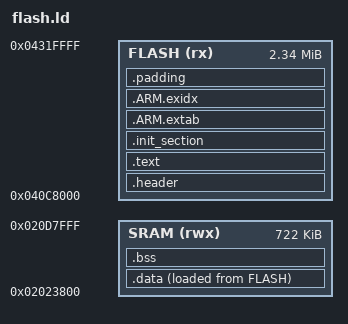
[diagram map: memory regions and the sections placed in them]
/****************************************************************************
 *
 * Copyright 2017 Samsung Electronics All Rights Reserved.
 *
 * Licensed under the Apache License, Version 2.0 (the "License");
 * you may not use this file except in compliance with the License.
 * You may obtain a copy of the License at
 *
 * http://www.apache.org/licenses/LICENSE-2.0
 *
 * Unless required by applicable law or agreed to in writing,
 * software distributed under the License is distributed on an
 * "AS IS" BASIS, WITHOUT WARRANTIES OR CONDITIONS OF ANY KIND,
 * either express or implied. See the License for the specific
 * language governing permissions and limitations under the License.
 *
 ****************************************************************************/
/****************************************************************************
 * configs/sidk_s5jt200/scripts/ld_s5jt200_flash.script
 *
 *   Copyright (C) 2011-2013 Gregory Nutt. All rights reserved.
 *   Author: Gregory Nutt <gnutt@nuttx.org>
 *           Laurent Latil <laurent@latil.nom.fr>
 *
 * Redistribution and use in source and binary forms, with or without
 * modification, are permitted provided that the following conditions
 * are met:
 *
 * 1. Redistributions of source code must retain the above copyright
 *    notice, this list of conditions and the following disclaimer.
 * 2. Redistributions in binary form must reproduce the above copyright
 *    notice, this list of conditions and the following disclaimer in
 *    the documentation and/or other materials provided with the
 *    distribution.
 * 3. Neither the name NuttX nor the names of its contributors may be
 *    used to endorse or promote products derived from this software
 *    without specific prior written permission.
 *
 * THIS SOFTWARE IS PROVIDED BY THE COPYRIGHT HOLDERS AND CONTRIBUTORS
 * "AS IS" AND ANY EXPRESS OR IMPLIED WARRANTIES, INCLUDING, BUT NOT
 * LIMITED TO, THE IMPLIED WARRANTIES OF MERCHANTABILITY AND FITNESS
 * FOR A PARTICULAR PURPOSE ARE DISCLAIMED. IN NO EVENT SHALL THE
 * COPYRIGHT OWNER OR CONTRIBUTORS BE LIABLE FOR ANY DIRECT, INDIRECT,
 * INCIDENTAL, SPECIAL, EXEMPLARY, OR CONSEQUENTIAL DAMAGES (INCLUDING,
 * BUT NOT LIMITED TO, PROCUREMENT OF SUBSTITUTE GOODS OR SERVICES; LOSS
 * OF USE, DATA, OR PROFITS; OR BUSINESS INTERRUPTION) HOWEVER CAUSED
 * AND ON ANY THEORY OF LIABILITY, WHETHER IN CONTRACT, STRICT
 * LIABILITY, OR TORT (INCLUDING NEGLIGENCE OR OTHERWISE) ARISING IN
 * ANY WAY OUT OF THE USE OF THIS SOFTWARE, EVEN IF ADVISED OF THE
 * POSSIBILITY OF SUCH DAMAGE.
 *
 ****************************************************************************/

MEMORY
{
	FLASH	(rx)	: ORIGIN = 0x040C8000, LENGTH = 2400K
	SRAM	(rwx)	: ORIGIN = 0x02023800, LENGTH = 722K
}

OUTPUT_FORMAT("elf32-littlearm", "elf32-littlearm", "elf32-littlearm")
OUTPUT_ARCH(arm)
ENTRY(_stext)
SECTIONS
{
	.header : {
		_start = .;
		LONG((_end - _start) / 512);
		LONG(0);
		LONG(0x656d6264);
		. = ALIGN(0x20);
	} > FLASH =0x0

	.text : {
		_stext = ABSOLUTE(.);
		*(.vectors)
		*(.text .text.*)
		*(.fixup)
		*(.gnu.warning)
		*(.rodata .rodata.*)
		*(.gnu.linkonce.t.*)
		*(.glue_7)
		*(.glue_7t)
		*(.got)
		*(.gcc_except_table)
		*(.gnu.linkonce.r.*)
		_etext = ABSOLUTE(.);
	} > FLASH

	.init_section : {
		_sinit = ABSOLUTE(.);
		*(.init_array .init_array.*)
		_einit = ABSOLUTE(.);
	} > FLASH

	.ARM.extab : {
		*(.ARM.extab*)
	} > FLASH

	__exidx_start = ABSOLUTE(.);
	.ARM.exidx : {
		*(.ARM.exidx*)
	} > FLASH
	__exidx_end = ABSOLUTE(.);

	_eronly = ABSOLUTE(.);

	.data : {
		_sdata = ABSOLUTE(.);
		*(.data .data.*)
		*(.gnu.linkonce.d.*)
		CONSTRUCTORS
		_edata = ABSOLUTE(.);
	} > SRAM AT > FLASH

	.bss : {
		_sbss = ABSOLUTE(.);
		*(.bss .bss.*)
		*(.gnu.linkonce.b.*)
		*(COMMON)
		. = ALIGN(4);
		_ebss = ABSOLUTE(.);
	} > SRAM

	/* Stabs debugging sections. */
	.stab 0 : { *(.stab) }
	.stabstr 0 : { *(.stabstr) }
	.stab.excl 0 : { *(.stab.excl) }
	.stab.exclstr 0 : { *(.stab.exclstr) }
	.stab.index 0 : { *(.stab.index) }
	.stab.indexstr 0 : { *(.stab.indexstr) }
	.comment 0 : { *(.comment) }
	.debug_abbrev 0 : { *(.debug_abbrev) }
	.debug_info 0 : { *(.debug_info) }
	.debug_line 0 : { *(.debug_line) }
	.debug_pubnames 0 : { *(.debug_pubnames) }
	.debug_aranges 0 : { *(.debug_aranges) }

	.padding : {
		. = ALIGN(512);
		. = . + 1020;
		LONG(0);
		_end = .;
	} > FLASH =0x0
}
